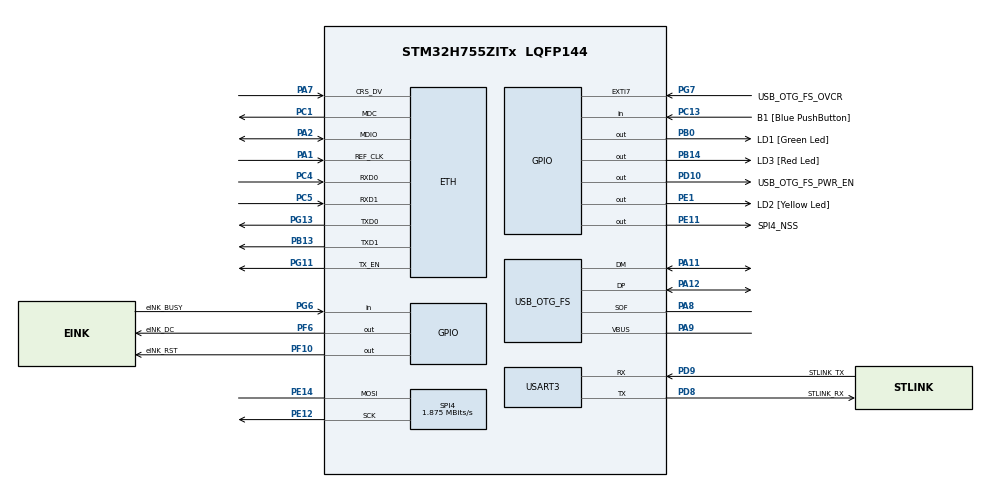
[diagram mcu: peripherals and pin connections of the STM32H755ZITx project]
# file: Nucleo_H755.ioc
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Mcu.Family=STM32H7
RCC.CortexFreq_Value=480000000
SPI4.VirtualType=VM_MASTER
PG7.PinAttribute=Free
PG6.Signal=GPIO_Input
RCC.HPRE=RCC_HCLK_DIV2
PH0-OSC_IN\ (PH0).PinAttribute=CortexM7
PH0-OSC_IN\ (PH0).Signal=RCC_OSC_IN
PE11.GPIO_Label=SPI4_NSS
PB14.GPIO_Label=LD3 [Red Led]
PC15-OSC32_OUT\ (OSC32_OUT).Mode=LSE-External-Oscillator
PG6.GPIO_Label=eINK_BUSY
RCC.PLLFRACN=0
SPI4.Direction=SPI_DIRECTION_1LINE
PA11.Mode=Device_Only
PB0.GPIO_Label=LD1 [Green Led]
RCC.PLL2FRACN=0
PC5.Mode=RMII
PC13.GPIO_Label=B1 [Blue PushButton]
PB13.Signal=ETH_TXD1
PG13.Signal=ETH_TXD0
PD9.Mode=Asynchronous
PF6.GPIO_Label=eINK_DC
PG11.Signal=ETH_TX_EN
RCC.SYSCLKSource=RCC_SYSCLKSOURCE_PLLCLK
ProjectManager.StackSize=0x400
USART3.VirtualMode-Asynchronous=VM_ASYNC
PA12.Signal=USB_OTG_FS_DP
SPI4.Mode=SPI_MODE_MASTER
RCC.HCLKFreq_Value=240000000
PE13.PinAttribute=CortexM7
PD8.Signal=USART3_TX
PE1.Signal=GPIO_Output
PF10.GPIO_Label=eINK_RST
PB0.PinAttribute=Free
RCC.HSE_VALUE=8000000
RCC.DIVM1=1
NVIC2.PriorityGroup=NVIC_PRIORITYGROUP_4
PE13.Signal=SPI4_MISO
PD8.PinAttribute=CortexM7
VP_SYS_M4_VS_Systick.Mode=SysTick
PA8.Signal=USB_OTG_FS_SOF
PG13.Mode=RMII
CortexM7.IPs=FATFS_M7\:I,FREERTOS_M7\:I,IWDG1\:I,RCC\:I,WWDG1\:I,DMA\:I,BDMA\:I,MDMA\:I,NVIC1\:I,ETH\:I,USART3\:I,USB_OTG_FS\:I,SYS\:I,CORTEX_M7\:I,DEBUG\:I,USB_DEVICE_M7\:I,USB_HOST_M7\:I,PDM2PCM_M7\:I,PWR\:I,RESMGR_UTILITY\:I,OPENAMP_M7\:I,VREFBUF\:I,SPI4\:I
PD10.PinAttribute=Free
SPI4.BaudRatePrescaler=SPI_BAUDRATEPRESCALER_64
RCC.APB3Freq_Value=120000000
PA7.PinAttribute=CortexM7
Mcu.Package=LQFP144
RCC.PLL3FRACN=0
RCC.D1PPRE=RCC_APB3_DIV2
USB_OTG_FS.VirtualMode=Device_Only
PC14-OSC32_IN\ (OSC32_IN).Mode=LSE-External-Oscillator
RCC.APB4Freq_Value=120000000
PE12.PinAttribute=CortexM7
PC5.Signal=ETH_RXD1
PB13.Mode=RMII
PH0-OSC_IN\ (PH0).Mode=HSE-External-Clock-Source
RCC.SupplySource=PWR_DIRECT_SMPS_SUPPLY
PC4.Mode=RMII
PH1-OSC_OUT\ (PH1).PinAttribute=CortexM7
PE12.Mode=Simplex_Bidirectional_Master
PB14.PinAttribute=Free
RCC.DIVQ1=20
PA7.Mode=RMII
PG7.Signal=GPXTI7
PD9.GPIO_Label=STLINK_TX
PA1.PinAttribute=CortexM7
SPI4.DataSize=SPI_DATASIZE_8BIT
PC13.Signal=GPIO_Input
PC4.Signal=ETH_RXD0
NVIC1.PriorityGroup=NVIC_PRIORITYGROUP_4
RCC.D2PPRE2=RCC_APB2_DIV2
RCC.D2PPRE1=RCC_APB1_DIV2
PD9.Signal=USART3_RX
PA9.PinAttribute=CortexM7
PH1-OSC_OUT\ (PH1).Signal=RCC_OSC_OUT
PG13.PinAttribute=CortexM7
PB13.PinAttribute=CortexM7
PD8.GPIO_Label=STLINK_RX
PD10.Signal=GPIO_Output
PA9.Mode=Activate_VBUS
PA12.PinAttribute=CortexM7
PF10.PinAttribute=Free
PF6.Signal=GPIO_Output
PA2.PinAttribute=CortexM7
ProjectManager.TargetToolchain=STM32CubeIDE
PC15-OSC32_OUT\ (OSC32_OUT).Signal=RCC_OSC32_OUT
PE11.PinAttribute=Free
PC14-OSC32_IN\ (OSC32_IN).PinAttribute=CortexM7
PA9.Signal=USB_OTG_FS_VBUS
RCC.DIVN1=120
PC4.PinAttribute=CortexM7
RCC.USBFreq_Value=48000000
PD10.GPIO_Label=USB_OTG_FS_PWR_EN
PE11.Signal=GPIO_Output
PD8.Mode=Asynchronous
PA1.Signal=ETH_REF_CLK
SPI4.NSSPMode=SPI_NSS_PULSE_DISABLE
PB14.Signal=GPIO_Output
board=NUCLEO-H755ZI-Q
PG11.PinAttribute=CortexM7
PE1.GPIO_Label=LD2 [Yellow Led]
RCC.APB2Freq_Value=120000000
PA1.Mode=RMII
PE14.Signal=SPI4_MOSI
PA11.PinAttribute=CortexM7
PF10.Signal=GPIO_Output
PG7.GPIO_Label=USB_OTG_FS_OVCR
PE14.Mode=Simplex_Bidirectional_Master
RCC.ADCFreq_Value=16125000
SPI4.CalculateBaudRate=1.875 MBits/s
PE1.PinAttribute=Free
Mcu.Name=STM32H755ZITx
PE12.Signal=SPI4_SCK
PA2.Signal=ETH_MDIO
PC13.PinAttribute=Free
RCC.SYSCLKFreq_VALUE=480000000
ETH.MediaInterface=HAL_ETH_RMII_MODE
PA8.PinAttribute=CortexM7
PA12.Mode=Device_Only
PC14-OSC32_IN\ (OSC32_IN).Signal=RCC_OSC32_IN
PG6.PinAttribute=Free
PG11.Mode=RMII
PA11.Signal=USB_OTG_FS_DM
ProjectManager.HeapSize=0x200
PF6.PinAttribute=Free
PD9.PinAttribute=CortexM7
PC15-OSC32_OUT\ (OSC32_OUT).PinAttribute=CortexM7
PA2.Mode=RMII
PC5.PinAttribute=CortexM7
RCC.D3PPRE=RCC_APB4_DIV2
PA8.Mode=Activate_SOF_FS
PE14.PinAttribute=CortexM7
PC1.PinAttribute=CortexM7
RCC.APB1Freq_Value=120000000
PB0.Signal=GPIO_Output
PC1.Signal=ETH_MDC
PC1.Mode=RMII
PA7.Signal=ETH_CRS_DV
CortexM4.IPs=FATFS_M4\:I,FREERTOS_M4\:I,IWDG2\:I,RCC,WWDG2\:I,DMA,BDMA,MDMA,NVIC2\:I,ETH,USART3,DEBUG,USB_DEVICE_M4\:I,USB_HOST_M4\:I,PDM2PCM_M4\:I,PWR,RESMGR_UTILITY,SYS_M4\:I,CORTEX_M4\:I,OPENAMP_M4\:I,VREFBUF

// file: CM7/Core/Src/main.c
/* USER CODE BEGIN Header */
/**
  ******************************************************************************
  * @file           : main.c
  * @brief          : Main program body
  ******************************************************************************
  * @attention
  *
  * <h2><center>&copy; Copyright (c) 2020 STMicroelectronics.
  * All rights reserved.</center></h2>
  *
  * This software component is licensed by ST under BSD 3-Clause license,
  * the "License"; You may not use this file except in compliance with the
  * License. You may obtain a copy of the License at:
  *                        opensource.org/licenses/BSD-3-Clause
  *
  ******************************************************************************
  */
/* USER CODE END Header */
#include "main.h"
#include "string.h"

/* USER CODE BEGIN Includes */
#include "eINK.h"
/* USER CODE END Includes */

/* USER CODE BEGIN PD */

#define HSEM_ID_0 (0U) /* HW semaphore 0*/
/* USER CODE END PD */

#if defined ( __ICCARM__ ) /*!< IAR Compiler */

#pragma location=0x30040000
ETH_DMADescTypeDef  DMARxDscrTab[ETH_RX_DESC_CNT]; /* Ethernet Rx DMA Descriptors */
#pragma location=0x30040060
ETH_DMADescTypeDef  DMATxDscrTab[ETH_TX_DESC_CNT]; /* Ethernet Tx DMA Descriptors */
#pragma location=0x30040200
uint8_t Rx_Buff[ETH_RX_DESC_CNT][ETH_MAX_PACKET_SIZE]; /* Ethernet Receive Buffers */

#elif defined ( __CC_ARM )  /* MDK ARM Compiler */

__attribute__((at(0x30040000))) ETH_DMADescTypeDef  DMARxDscrTab[ETH_RX_DESC_CNT]; /* Ethernet Rx DMA Descriptors */
__attribute__((at(0x30040060))) ETH_DMADescTypeDef  DMATxDscrTab[ETH_TX_DESC_CNT]; /* Ethernet Tx DMA Descriptors */
__attribute__((at(0x30040200))) uint8_t Rx_Buff[ETH_RX_DESC_CNT][ETH_MAX_PACKET_SIZE]; /* Ethernet Receive Buffer */

#elif defined ( __GNUC__ ) /* GNU Compiler */

ETH_DMADescTypeDef DMARxDscrTab[ETH_RX_DESC_CNT] __attribute__((section(".RxDecripSection"))); /* Ethernet Rx DMA Descriptors */
ETH_DMADescTypeDef DMATxDscrTab[ETH_TX_DESC_CNT] __attribute__((section(".TxDecripSection")));   /* Ethernet Tx DMA Descriptors */
uint8_t Rx_Buff[ETH_RX_DESC_CNT][ETH_MAX_PACKET_SIZE] __attribute__((section(".RxArraySection"))); /* Ethernet Receive Buffers */

#endif

ETH_TxPacketConfig TxConfig;

ETH_HandleTypeDef heth;

SPI_HandleTypeDef hspi4;

UART_HandleTypeDef huart3;

PCD_HandleTypeDef hpcd_USB_OTG_FS;

void SystemClock_Config(void);
static void MX_GPIO_Init(void);
static void MX_ETH_Init(void);
static void MX_USART3_UART_Init(void);
static void MX_USB_OTG_FS_PCD_Init(void);
static void MX_SPI4_Init(void);

int main(void)
{

/* USER CODE BEGIN Boot_Mode_Sequence_0 */
  int32_t timeout;
/* USER CODE END Boot_Mode_Sequence_0 */

/* USER CODE BEGIN Boot_Mode_Sequence_1 */
  /* Wait until CPU2 boots and enters in stop mode or timeout*/
  timeout = 0xFFFF;
  while((__HAL_RCC_GET_FLAG(RCC_FLAG_D2CKRDY) != RESET) && (timeout-- > 0));
  if ( timeout < 0 )
  {
  Error_Handler();
  }
/* USER CODE END Boot_Mode_Sequence_1 */
  /* MCU Configuration--------------------------------------------------------*/

  /* Reset of all peripherals, Initializes the Flash interface and the Systick. */
  HAL_Init();

  /* Configure the system clock */
  SystemClock_Config();
/* USER CODE BEGIN Boot_Mode_Sequence_2 */
/* When system initialization is finished, Cortex-M7 will release Cortex-M4 by means of
HSEM notification */
/*HW semaphore Clock enable*/
__HAL_RCC_HSEM_CLK_ENABLE();
/*Take HSEM */
HAL_HSEM_FastTake(HSEM_ID_0);
/*Release HSEM in order to notify the CPU2(CM4)*/
HAL_HSEM_Release(HSEM_ID_0,0);
/* wait until CPU2 wakes up from stop mode */
timeout = 0xFFFF;
while((__HAL_RCC_GET_FLAG(RCC_FLAG_D2CKRDY) == RESET) && (timeout-- > 0));
if ( timeout < 0 )
{
Error_Handler();
}
/* USER CODE END Boot_Mode_Sequence_2 */

  /* Initialize all configured peripherals */
  MX_GPIO_Init();
  MX_ETH_Init();
  MX_USART3_UART_Init();
  MX_USB_OTG_FS_PCD_Init();
  MX_SPI4_Init();
  /* USER CODE BEGIN 2 */
  _main();
  /* USER CODE END 2 */

  /* Infinite loop */
  while (1)
  {

  }
}

void SystemClock_Config(void)
{
  RCC_OscInitTypeDef RCC_OscInitStruct = {0};
  RCC_ClkInitTypeDef RCC_ClkInitStruct = {0};
  RCC_PeriphCLKInitTypeDef PeriphClkInitStruct = {0};

  /** Supply configuration update enable
  */
  HAL_PWREx_ConfigSupply(PWR_DIRECT_SMPS_SUPPLY);
  /** Configure the main internal regulator output voltage
  */
  __HAL_PWR_VOLTAGESCALING_CONFIG(PWR_REGULATOR_VOLTAGE_SCALE0);

  while(!__HAL_PWR_GET_FLAG(PWR_FLAG_VOSRDY)) {}
  /** Initializes the RCC Oscillators according to the specified parameters
  * in the RCC_OscInitTypeDef structure.
  */
  RCC_OscInitStruct.OscillatorType = RCC_OSCILLATORTYPE_HSE;
  RCC_OscInitStruct.HSEState = RCC_HSE_BYPASS;
  RCC_OscInitStruct.PLL.PLLState = RCC_PLL_ON;
  RCC_OscInitStruct.PLL.PLLSource = RCC_PLLSOURCE_HSE;
  RCC_OscInitStruct.PLL.PLLM = 1;
  RCC_OscInitStruct.PLL.PLLN = 120;
  RCC_OscInitStruct.PLL.PLLP = 2;
  RCC_OscInitStruct.PLL.PLLQ = 20;
  RCC_OscInitStruct.PLL.PLLR = 2;
  RCC_OscInitStruct.PLL.PLLRGE = RCC_PLL1VCIRANGE_3;
  RCC_OscInitStruct.PLL.PLLVCOSEL = RCC_PLL1VCOWIDE;
  RCC_OscInitStruct.PLL.PLLFRACN = 0;
  if (HAL_RCC_OscConfig(&RCC_OscInitStruct) != HAL_OK)
  {
    Error_Handler();
  }
  /** Initializes the CPU, AHB and APB buses clocks
  */
  RCC_ClkInitStruct.ClockType = RCC_CLOCKTYPE_HCLK|RCC_CLOCKTYPE_SYSCLK
                              |RCC_CLOCKTYPE_PCLK1|RCC_CLOCKTYPE_PCLK2
                              |RCC_CLOCKTYPE_D3PCLK1|RCC_CLOCKTYPE_D1PCLK1;
  RCC_ClkInitStruct.SYSCLKSource = RCC_SYSCLKSOURCE_PLLCLK;
  RCC_ClkInitStruct.SYSCLKDivider = RCC_SYSCLK_DIV1;
  RCC_ClkInitStruct.AHBCLKDivider = RCC_HCLK_DIV2;
  RCC_ClkInitStruct.APB3CLKDivider = RCC_APB3_DIV2;
  RCC_ClkInitStruct.APB1CLKDivider = RCC_APB1_DIV2;
  RCC_ClkInitStruct.APB2CLKDivider = RCC_APB2_DIV2;
  RCC_ClkInitStruct.APB4CLKDivider = RCC_APB4_DIV2;

  if (HAL_RCC_ClockConfig(&RCC_ClkInitStruct, FLASH_LATENCY_4) != HAL_OK)
  {
    Error_Handler();
  }
  PeriphClkInitStruct.PeriphClockSelection = RCC_PERIPHCLK_USART3|RCC_PERIPHCLK_SPI4
                              |RCC_PERIPHCLK_USB;
  PeriphClkInitStruct.Spi45ClockSelection = RCC_SPI45CLKSOURCE_D2PCLK1;
  PeriphClkInitStruct.Usart234578ClockSelection = RCC_USART234578CLKSOURCE_D2PCLK1;
  PeriphClkInitStruct.UsbClockSelection = RCC_USBCLKSOURCE_PLL;
  if (HAL_RCCEx_PeriphCLKConfig(&PeriphClkInitStruct) != HAL_OK)
  {
    Error_Handler();
  }
  /** Enable USB Voltage detector
  */
  HAL_PWREx_EnableUSBVoltageDetector();
}

static void MX_ETH_Init(void)
{

  heth.Instance = ETH;
  heth.Init.MACAddr[0] =   0x00;
  heth.Init.MACAddr[1] =   0x80;
  heth.Init.MACAddr[2] =   0xE1;
  heth.Init.MACAddr[3] =   0x00;
  heth.Init.MACAddr[4] =   0x00;
  heth.Init.MACAddr[5] =   0x00;
  heth.Init.MediaInterface = HAL_ETH_RMII_MODE;
  heth.Init.TxDesc = DMATxDscrTab;
  heth.Init.RxDesc = DMARxDscrTab;
  heth.Init.RxBuffLen = 1524;

  if (HAL_ETH_Init(&heth) != HAL_OK)
  {
    Error_Handler();
  }

  memset(&TxConfig, 0 , sizeof(ETH_TxPacketConfig));
  TxConfig.Attributes = ETH_TX_PACKETS_FEATURES_CSUM | ETH_TX_PACKETS_FEATURES_CRCPAD;
  TxConfig.ChecksumCtrl = ETH_CHECKSUM_IPHDR_PAYLOAD_INSERT_PHDR_CALC;
  TxConfig.CRCPadCtrl = ETH_CRC_PAD_INSERT;

}

static void MX_SPI4_Init(void)
{

  /* SPI4 parameter configuration*/
  hspi4.Instance = SPI4;
  hspi4.Init.Mode = SPI_MODE_MASTER;
  hspi4.Init.Direction = SPI_DIRECTION_1LINE;
  hspi4.Init.DataSize = SPI_DATASIZE_8BIT;
  hspi4.Init.CLKPolarity = SPI_POLARITY_LOW;
  hspi4.Init.CLKPhase = SPI_PHASE_1EDGE;
  hspi4.Init.NSS = SPI_NSS_SOFT;
  hspi4.Init.BaudRatePrescaler = SPI_BAUDRATEPRESCALER_64;
  hspi4.Init.FirstBit = SPI_FIRSTBIT_MSB;
  hspi4.Init.TIMode = SPI_TIMODE_DISABLE;
  hspi4.Init.CRCCalculation = SPI_CRCCALCULATION_DISABLE;
  hspi4.Init.CRCPolynomial = 0x0;
  hspi4.Init.NSSPMode = SPI_NSS_PULSE_DISABLE;
  hspi4.Init.NSSPolarity = SPI_NSS_POLARITY_LOW;
  hspi4.Init.FifoThreshold = SPI_FIFO_THRESHOLD_01DATA;
  hspi4.Init.TxCRCInitializationPattern = SPI_CRC_INITIALIZATION_ALL_ZERO_PATTERN;
  hspi4.Init.RxCRCInitializationPattern = SPI_CRC_INITIALIZATION_ALL_ZERO_PATTERN;
  hspi4.Init.MasterSSIdleness = SPI_MASTER_SS_IDLENESS_00CYCLE;
  hspi4.Init.MasterInterDataIdleness = SPI_MASTER_INTERDATA_IDLENESS_00CYCLE;
  hspi4.Init.MasterReceiverAutoSusp = SPI_MASTER_RX_AUTOSUSP_DISABLE;
  hspi4.Init.MasterKeepIOState = SPI_MASTER_KEEP_IO_STATE_DISABLE;
  hspi4.Init.IOSwap = SPI_IO_SWAP_DISABLE;
  if (HAL_SPI_Init(&hspi4) != HAL_OK)
  {
    Error_Handler();
  }

}

static void MX_USART3_UART_Init(void)
{

  huart3.Instance = USART3;
  huart3.Init.BaudRate = 115200;
  huart3.Init.WordLength = UART_WORDLENGTH_8B;
  huart3.Init.StopBits = UART_STOPBITS_1;
  huart3.Init.Parity = UART_PARITY_NONE;
  huart3.Init.Mode = UART_MODE_TX_RX;
  huart3.Init.HwFlowCtl = UART_HWCONTROL_NONE;
  huart3.Init.OverSampling = UART_OVERSAMPLING_16;
  huart3.Init.OneBitSampling = UART_ONE_BIT_SAMPLE_DISABLE;
  huart3.Init.ClockPrescaler = UART_PRESCALER_DIV1;
  huart3.AdvancedInit.AdvFeatureInit = UART_ADVFEATURE_NO_INIT;
  if (HAL_UART_Init(&huart3) != HAL_OK)
  {
    Error_Handler();
  }
  if (HAL_UARTEx_SetTxFifoThreshold(&huart3, UART_TXFIFO_THRESHOLD_1_8) != HAL_OK)
  {
    Error_Handler();
  }
  if (HAL_UARTEx_SetRxFifoThreshold(&huart3, UART_RXFIFO_THRESHOLD_1_8) != HAL_OK)
  {
    Error_Handler();
  }
  if (HAL_UARTEx_DisableFifoMode(&huart3) != HAL_OK)
  {
    Error_Handler();
  }

}

static void MX_USB_OTG_FS_PCD_Init(void)
{

  hpcd_USB_OTG_FS.Instance = USB_OTG_FS;
  hpcd_USB_OTG_FS.Init.dev_endpoints = 9;
  hpcd_USB_OTG_FS.Init.speed = PCD_SPEED_FULL;
  hpcd_USB_OTG_FS.Init.dma_enable = DISABLE;
  hpcd_USB_OTG_FS.Init.phy_itface = PCD_PHY_EMBEDDED;
  hpcd_USB_OTG_FS.Init.Sof_enable = DISABLE;
  hpcd_USB_OTG_FS.Init.low_power_enable = DISABLE;
  hpcd_USB_OTG_FS.Init.lpm_enable = DISABLE;
  hpcd_USB_OTG_FS.Init.battery_charging_enable = ENABLE;
  hpcd_USB_OTG_FS.Init.vbus_sensing_enable = ENABLE;
  hpcd_USB_OTG_FS.Init.use_dedicated_ep1 = DISABLE;
  if (HAL_PCD_Init(&hpcd_USB_OTG_FS) != HAL_OK)
  {
    Error_Handler();
  }

}

static void MX_GPIO_Init(void)
{

  /* GPIO Ports Clock Enable */
  __HAL_RCC_GPIOC_CLK_ENABLE();
  __HAL_RCC_GPIOH_CLK_ENABLE();
  __HAL_RCC_GPIOA_CLK_ENABLE();
  __HAL_RCC_GPIOE_CLK_ENABLE();
  __HAL_RCC_GPIOB_CLK_ENABLE();
  __HAL_RCC_GPIOD_CLK_ENABLE();
  __HAL_RCC_GPIOG_CLK_ENABLE();

}

void Error_Handler(void)
{
}

/************************ (C) COPYRIGHT STMicroelectronics *****END OF FILE****/
